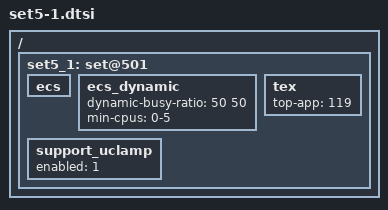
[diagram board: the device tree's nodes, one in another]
/ {
	/* camera mode - touch boost */
	set5_1: set@501 {
		ecs { };

		ecs_dynamic {
			dynamic-busy-ratio	= <50 50>;
			min-cpus = "0-5";
		};

		tex {
			top-app = <119>;
		};

		support_uclamp {
			enabled = <1>;
		};
	};
};
